# WBZ450 register map
Vendor: Microchip
Architecture arm32bit. Special function registers and configuration words.
Registers are 32-bit, read-write, reset 0x0 unless marked. A register's access mark holds for its fields unless they carry their own. Addresses are absolute, and some are shared; only a register's first bit layout is shown; lines under a group give offsets from that group; [hi:lo] are bit positions; {n}, {i} and the like mark numbered series; 'fields as' and 'values as' point back to an identical list; <NAME> marks a mode.

## Further device data
pins=1: GND; 2: NMCLR; 3: PB0; 4: AVDD; 5: GND; 6: PA4; 7: PA3; 8: GND; 9: PB5; 10: PB1; 11: PB4; 12: PB6; 13: PB8; 14: PB9; 15: PB7; 16: VDD; 17: VDD; 18: GND; 19: PA5; 20: PA6; 21: GND; 22: PA9; 23: PA10/RPA10/IN0/IN3/EXTINT0/EXTINT3/NMI/OUT1/RTC_OUT_ALT/SERCOM1_PAD3; 24: PA8; 25: PA7; 26: NC; 27: GND; 28: NC; 29: NC; 30: NC, interrupts=-15 Reset — Reset Vector, invoked on Power up and warm reset; -14 NonMaskableInt — Non maskable Interrupt, cannot be stopped or preempted; -13 HardFault — Hard Fault, all classes of Fault; -12 MemoryManagement — Memory Management, MPU mismatch, including Access Violation and No Match; -11 BusFault — Bus Fault, Pre-Fetch-, Memory Access Fault, other address/memory related Fault; -10 UsageFault — Usage Fault, i.e. Undef Instruction, Illegal State Transition; -5 SVCall — System Service Call via SVC instruction; -4 DebugMonitor — Debug Monitor; -2 PendSV — Pendable request for system service; -1 SysTick — System Tick Timer; 0 RTC — Real Time Counter; 1 EIC — External Interrupt Controller; 2 FREQM — Frequency Meter; 3 FLASH_CONTROL — Non-Volatile Memory; 4 CHANGE_NOTICE_A — PORT_A_INPUT_CHANGE_INTERRUPT; 5 CHANGE_NOTICE_B — PORT_B_INPUT_CHANGE_INTERRUPT; 6 DMAC_0_3 — DMA Channel 0..3; 7 DMAC_4_15 — DMA Channel 4..X; 8 EVSYS_0_3 — Event System Channel 0..3; 9 EVSYS_4_11 — Event System Channel 4..X; 10 PAC — Peripheral Access Controller; 11 RAMECC — RAM Error Correction Code; 12 SERCOM0 — Serial Communication Interface 0; 13 SERCOM1 — Serial Communication Interface 1; 16 TCC0 — Timer/Counter for Control Applications 0; 17 TCC1 — Timer/Counter for Control Applications 1; 18 TCC2 — Timer/Counter for Control Applications 2; 19 TC0 — Timer/Counter 0; 20 TC1 — Timer/Counter 1; 21 TC2 — Timer/Counter 2; 22 TC3 — Timer/Counter 3; 23 ADCHS — Analog-to-Digital Converter; 25 AES — Advanced Encryption Standard; 26 TRNG — True Random Generator; 27 ICM — Integrity Check Monitor; 28 PUKCC — Public-Key Cryptography Controller; 29 QSPI — Quad SPI interface; 30 ZB_INT0 — ZIGBEE; 31 BT_INT0 — Bluetooth 0; 32 BT_INT1 — Bluetooth 0; 33 ARBITER — Radio Arbiter; 34 ADC_FAULT — ADC Fault Interrupt; 35 ADC_FCC — ADC FCC Interrupt; 36 ADC_BGVR_RDY — ADC BGVR Ready; 37 CLKI_WAKEUP_NMI — Bluetooth WAKEUP; 38 BT_LC — Bluetooth LC; 39 BT_RC — Bluetooth RC

## PAC
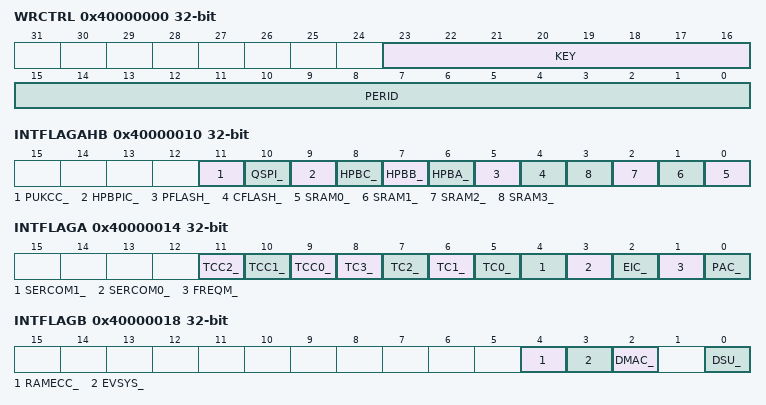
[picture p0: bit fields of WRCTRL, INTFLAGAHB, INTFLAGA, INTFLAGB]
0x40000000 WRCTRL
  [23:16] KEY — Peripheral access control key
    0=OFF (No action); 1=CLR (Clear protection); 2=SET (Set protection); 3=SETLCK (Set and lock protection)
  [15:0] PERID — Peripheral identifier
0x40000004 EVCTRL 8-bit
  [0] ERREO — Peripheral acess error event output
0x40000008 INTENCLR 8-bit
  [0] ERR — Peripheral access error interrupt disable
0x40000009 INTENSET 8-bit
  [0] ERR — Peripheral access error interrupt enable
0x40000010 INTFLAGAHB
  [11] PUKCC_
  [10] QSPI_
  [9] HPBPIC_ — HPBPIC0
  [8] HPBC_
  [7] HPBB_
  [6] HPBA_
  [5] PFLASH_
  [4] CFLASH_
  [n] SRAM{n}_ (n=0..3)
0x40000014 INTFLAGA
  [11] TCC2_, [10] TCC1_, [9] TCC0_, [n+5] TC{n}_ (n=0..3), [4] SERCOM1_, [3] SERCOM0_, [2] EIC_, [1] FREQM_, [0] PAC_
0x40000018 INTFLAGB
  [4] RAMECC_, [3] EVSYS_, [2] DMAC_, [0] DSU_
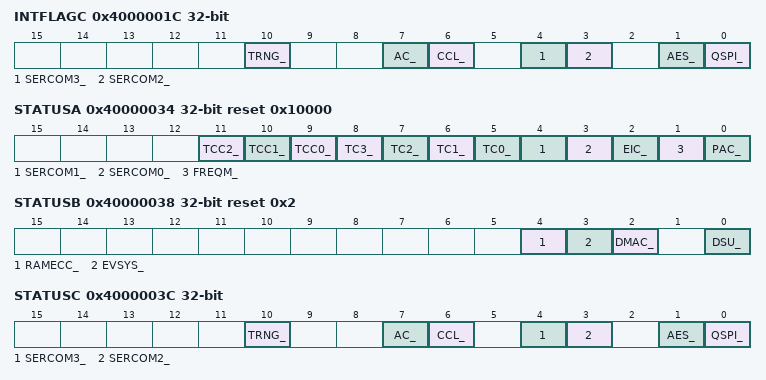
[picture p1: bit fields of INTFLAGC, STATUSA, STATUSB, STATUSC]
0x4000001C INTFLAGC
  [10] TRNG_, [7] AC_, [6] CCL_, [4] SERCOM3_, [3] SERCOM2_, [1] AES_, [0] QSPI_
0x40000034 STATUSA ro reset 0x10000
  [11] TCC2_ — TCC2 APB Protect Enable
  [10] TCC1_ — TCC1 APB Protect Enable
  [9] TCC0_ — TCC0 APB Protect Enable
  [n+5] TC{n}_ (n=0..3) — TC{n} APB Protect Enable
  [4] SERCOM1_ — SERCOM1 APB Protect Enable
  [3] SERCOM0_ — SERCOM0 APB Protect Enable
  [2] EIC_ — EIC APB Protect Enable
  [1] FREQM_ — FREQM APB Protect Enable
  [0] PAC_ — PAC APB Protect Enable
0x40000038 STATUSB ro reset 0x2
  [4] RAMECC_ — RAMECC APB Protect Enable
  [3] EVSYS_ — EVSYS APB Protect Enable
  [2] DMAC_ — DMAC APB Protect Enable
  [0] DSU_ — DSU APB Protect Enable
0x4000003C STATUSC ro
  [10] TRNG_ — TRNG APB Protect Enable
  [7] AC_ — AC APB Protect Enable
  [6] CCL_ — CCL APB Protect Enable
  [4] SERCOM3_ — SERCOM3 APB Protect Enable
  [3] SERCOM2_ — SERCOM2 APB Protect Enable
  [1] AES_ — AES APB Protect Enable
  [0] QSPI_ — QSPI APB Protect Enable
